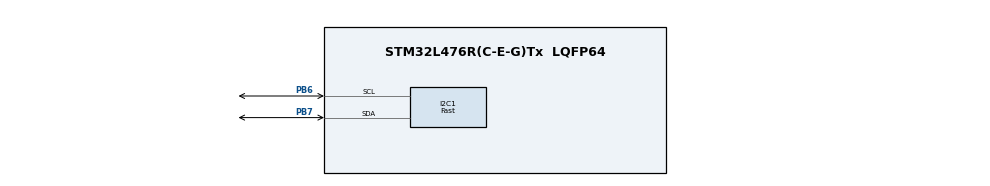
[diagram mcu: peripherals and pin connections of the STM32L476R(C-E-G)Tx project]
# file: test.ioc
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FREERTOS.Tasks01=defaultTask,0,128,StartDefaultTask,Default,NULL,Dynamic,NULL,NULL;myTask02,-3,128,StartTask02,Default,NULL,Dynamic,NULL,NULL
I2C1.I2C_Speed_Mode=I2C_Fast
I2C1.Timing=0x00000004
Mcu.Family=STM32L4
Mcu.Name=STM32L476R(C-E-G)Tx
Mcu.Package=LQFP64
NVIC.PriorityGroup=NVIC_PRIORITYGROUP_4
NVIC.TIM1_UP_TIM16_IRQn=true\:0\:0\:false\:false\:true\:false\:false\:true
NVIC.TimeBase=TIM1_UP_TIM16_IRQn
NVIC.TimeBaseIP=TIM1
PA13\ (JTMS-SWDIO).Mode=Trace_Asynchronous_SW
PA13\ (JTMS-SWDIO).Signal=SYS_JTMS-SWDIO
PA14\ (JTCK-SWCLK).Mode=Trace_Asynchronous_SW
PA14\ (JTCK-SWCLK).Signal=SYS_JTCK-SWCLK
PB3\ (JTDO-TRACESWO).Mode=Trace_Asynchronous_SW
PB3\ (JTDO-TRACESWO).Signal=SYS_JTDO-SWO
PB6.Mode=I2C
PB6.Signal=I2C1_SCL
PB7.Mode=I2C
PB7.Signal=I2C1_SDA
ProjectManager.HeapSize=0x200
ProjectManager.StackSize=0x400
ProjectManager.TargetToolchain=STM32CubeIDE
RCC.HSE_VALUE=8000000
RCC.HSI_VALUE=16000000
RCC.LSE_VALUE=32768
RCC.MSI_VALUE=4000000
RCC.VCOOutputFreq_Value=32000000
VP_FREERTOS_VS_CMSIS_V1.Mode=CMSIS_V1
VP_SYS_VS_tim1.Mode=TIM1
board=custom

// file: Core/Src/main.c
/* USER CODE BEGIN Header */
/**
  ******************************************************************************
  * @file           : main.c
  * @brief          : Main program body
  ******************************************************************************
  * @attention
  *
  * <h2><center>&copy; Copyright (c) 2020 STMicroelectronics.
  * All rights reserved.</center></h2>
  *
  * This software component is licensed by ST under BSD 3-Clause license,
  * the "License"; You may not use this file except in compliance with the
  * License. You may obtain a copy of the License at:
  *                        opensource.org/licenses/BSD-3-Clause
  *
  ******************************************************************************
  */
/* USER CODE END Header */
#include "main.h"
#include "cmsis_os.h"

I2C_HandleTypeDef hi2c1;

osThreadId defaultTaskHandle;
osThreadId myTask02Handle;

void SystemClock_Config(void);
static void MX_GPIO_Init(void);
static void MX_I2C1_Init(void);
void StartDefaultTask(void const * argument);
void StartTask02(void const * argument);

int main(void)
{

  /* MCU Configuration--------------------------------------------------------*/

  /* Reset of all peripherals, Initializes the Flash interface and the Systick. */
  HAL_Init();

  /* Configure the system clock */
  SystemClock_Config();

  /* Initialize all configured peripherals */
  MX_GPIO_Init();
  MX_I2C1_Init();

  /* Create the thread(s) */
  /* definition and creation of defaultTask */
  osThreadDef(defaultTask, StartDefaultTask, osPriorityNormal, 0, 128);
  defaultTaskHandle = osThreadCreate(osThread(defaultTask), NULL);

  /* definition and creation of myTask02 */
  osThreadDef(myTask02, StartTask02, osPriorityIdle, 0, 128);
  myTask02Handle = osThreadCreate(osThread(myTask02), NULL);

  /* Start scheduler */
  osKernelStart();

  /* We should never get here as control is now taken by the scheduler */
  /* Infinite loop */
  /* USER CODE BEGIN WHILE */
  while (1)
  {
	  HAL_Delay(100);
	  n++;
	  printf("test mood on %d\n",n);

    /* USER CODE END WHILE */

  }
}

void SystemClock_Config(void)
{
  RCC_OscInitTypeDef RCC_OscInitStruct = {0};
  RCC_ClkInitTypeDef RCC_ClkInitStruct = {0};
  RCC_PeriphCLKInitTypeDef PeriphClkInit = {0};

  /** Initializes the RCC Oscillators according to the specified parameters
  * in the RCC_OscInitTypeDef structure.
  */
  RCC_OscInitStruct.OscillatorType = RCC_OSCILLATORTYPE_MSI;
  RCC_OscInitStruct.MSIState = RCC_MSI_ON;
  RCC_OscInitStruct.MSICalibrationValue = 0;
  RCC_OscInitStruct.MSIClockRange = RCC_MSIRANGE_6;
  RCC_OscInitStruct.PLL.PLLState = RCC_PLL_NONE;
  if (HAL_RCC_OscConfig(&RCC_OscInitStruct) != HAL_OK)
  {
    Error_Handler();
  }
  /** Initializes the CPU, AHB and APB buses clocks
  */
  RCC_ClkInitStruct.ClockType = RCC_CLOCKTYPE_HCLK|RCC_CLOCKTYPE_SYSCLK
                              |RCC_CLOCKTYPE_PCLK1|RCC_CLOCKTYPE_PCLK2;
  RCC_ClkInitStruct.SYSCLKSource = RCC_SYSCLKSOURCE_MSI;
  RCC_ClkInitStruct.AHBCLKDivider = RCC_SYSCLK_DIV1;
  RCC_ClkInitStruct.APB1CLKDivider = RCC_HCLK_DIV1;
  RCC_ClkInitStruct.APB2CLKDivider = RCC_HCLK_DIV1;

  if (HAL_RCC_ClockConfig(&RCC_ClkInitStruct, FLASH_LATENCY_0) != HAL_OK)
  {
    Error_Handler();
  }
  PeriphClkInit.PeriphClockSelection = RCC_PERIPHCLK_I2C1;
  PeriphClkInit.I2c1ClockSelection = RCC_I2C1CLKSOURCE_PCLK1;
  if (HAL_RCCEx_PeriphCLKConfig(&PeriphClkInit) != HAL_OK)
  {
    Error_Handler();
  }
  /** Configure the main internal regulator output voltage
  */
  if (HAL_PWREx_ControlVoltageScaling(PWR_REGULATOR_VOLTAGE_SCALE1) != HAL_OK)
  {
    Error_Handler();
  }
}

static void MX_I2C1_Init(void)
{

  hi2c1.Instance = I2C1;
  hi2c1.Init.Timing = 0x00000004;
  hi2c1.Init.OwnAddress1 = 0;
  hi2c1.Init.AddressingMode = I2C_ADDRESSINGMODE_7BIT;
  hi2c1.Init.DualAddressMode = I2C_DUALADDRESS_DISABLE;
  hi2c1.Init.OwnAddress2 = 0;
  hi2c1.Init.OwnAddress2Masks = I2C_OA2_NOMASK;
  hi2c1.Init.GeneralCallMode = I2C_GENERALCALL_DISABLE;
  hi2c1.Init.NoStretchMode = I2C_NOSTRETCH_DISABLE;
  if (HAL_I2C_Init(&hi2c1) != HAL_OK)
  {
    Error_Handler();
  }
  /** Configure Analogue filter
  */
  if (HAL_I2CEx_ConfigAnalogFilter(&hi2c1, I2C_ANALOGFILTER_ENABLE) != HAL_OK)
  {
    Error_Handler();
  }
  /** Configure Digital filter
  */
  if (HAL_I2CEx_ConfigDigitalFilter(&hi2c1, 0) != HAL_OK)
  {
    Error_Handler();
  }

}

static void MX_GPIO_Init(void)
{

  /* GPIO Ports Clock Enable */
  __HAL_RCC_GPIOA_CLK_ENABLE();
  __HAL_RCC_GPIOB_CLK_ENABLE();

}

void StartDefaultTask(void const * argument)
{
  /* USER CODE BEGIN 5 */
  /* Infinite loop */
  for(;;)
  {
	  SSD1306_Clear();
	  SSD1306_GotoXY (10,10); // goto 10, 10
	  SSD1306_Puts ("MISHU LOVE", &Font_11x18, 1); // print Hello
	  SSD1306_UpdateScreen(); // update screen
	  SSD1306_GotoXY (10, 20);

	  SSD1306_GotoXY (10, 30);
	  SSD1306_Puts ("SAIRA", &Font_11x18, 1);
	  SSD1306_UpdateScreen(); // update screen

//	n++;
//	printf("test mood on default task = %d\n",n);
    osDelay(2000);

  }
  /* USER CODE END 5 */
}

void StartTask02(void const * argument)
{
  /* USER CODE BEGIN StartTask02 */
  /* Infinite loop */
  for(;;)
  {
//		m++;
//		printf("test mood on task 2 = %d\n",m);

	  SSD1306_Clear();
	  SSD1306_GotoXY (10,10); // goto 10, 10
	  SSD1306_Puts ("SAIRA LOVE ", &Font_11x18, 1); // print Hello
	  SSD1306_UpdateScreen(); // update screen
	  SSD1306_GotoXY (10, 20);

	  SSD1306_GotoXY (10, 30);
	  SSD1306_Puts ("MISHU", &Font_11x18, 1);
	  SSD1306_UpdateScreen(); // update screen

	  osDelay(2000);

  }
  /* USER CODE END StartTask02 */
}

 /**
  * @brief  Period elapsed callback in non blocking mode
  * @note   This function is called  when TIM1 interrupt took place, inside
  * HAL_TIM_IRQHandler(). It makes a direct call to HAL_IncTick() to increment
  * a global variable "uwTick" used as application time base.
  * @param  htim : TIM handle
  * @retval None
  */
void HAL_TIM_PeriodElapsedCallback(TIM_HandleTypeDef *htim)
{
  if (htim->Instance == TIM1) {
    HAL_IncTick();
  }
}

void Error_Handler(void)
{
}

/************************ (C) COPYRIGHT STMicroelectronics *****END OF FILE****/
